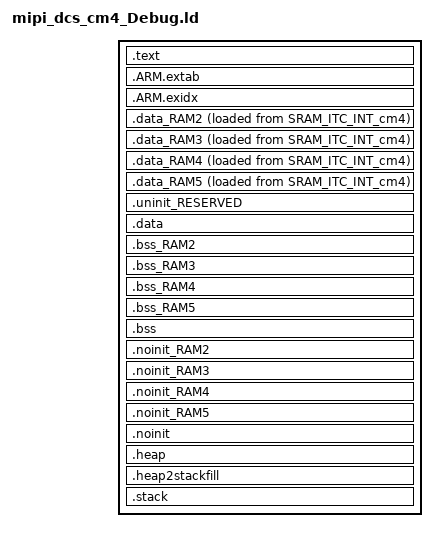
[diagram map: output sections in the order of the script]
/*
 * GENERATED FILE - DO NOT EDIT
 * Copyright 2008-2013 Code Red Technologies Ltd,
 * Copyright 2013-2024 NXP
 * Generated linker script file for MIMXRT1176xxxxx
 * Created from linkscript.ldt by FMCreateLinkLibraries
 * Using Freemarker v2.3.30
 * MCUXpresso IDE v11.8.0 [Build 1165] [2023-07-26] on May 7, 2024, 4:38:27 PM
 */

INCLUDE "mipi_dcs_cm4_Debug_library.ld"
INCLUDE "mipi_dcs_cm4_Debug_memory.ld"

ENTRY(ResetISR)

SECTIONS
{
     /* MAIN TEXT SECTION */
    .text : ALIGN(4)
    {
        FILL(0xff)
        __vectors_start__ = ABSOLUTE(.) ;
        KEEP(*(.isr_vector))
        /* Global Section Table */
        . = ALIGN(4) ;
        __section_table_start = .;
        __data_section_table = .;
        LONG(LOADADDR(.data));
        LONG(    ADDR(.data));
        LONG(  SIZEOF(.data));
        LONG(LOADADDR(.data_RAM2));
        LONG(    ADDR(.data_RAM2));
        LONG(  SIZEOF(.data_RAM2));
        LONG(LOADADDR(.data_RAM3));
        LONG(    ADDR(.data_RAM3));
        LONG(  SIZEOF(.data_RAM3));
        LONG(LOADADDR(.data_RAM4));
        LONG(    ADDR(.data_RAM4));
        LONG(  SIZEOF(.data_RAM4));
        LONG(LOADADDR(.data_RAM5));
        LONG(    ADDR(.data_RAM5));
        LONG(  SIZEOF(.data_RAM5));
        __data_section_table_end = .;
        __bss_section_table = .;
        LONG(    ADDR(.bss));
        LONG(  SIZEOF(.bss));
        LONG(    ADDR(.bss_RAM2));
        LONG(  SIZEOF(.bss_RAM2));
        LONG(    ADDR(.bss_RAM3));
        LONG(  SIZEOF(.bss_RAM3));
        LONG(    ADDR(.bss_RAM4));
        LONG(  SIZEOF(.bss_RAM4));
        LONG(    ADDR(.bss_RAM5));
        LONG(  SIZEOF(.bss_RAM5));
        __bss_section_table_end = .;
        __section_table_end = . ;
        /* End of Global Section Table */

        *(.after_vectors*)

       *(.text*)
       *(.rodata .rodata.* .constdata .constdata.*)
       . = ALIGN(4);
    } > SRAM_ITC_INT_cm4
    /*
     * for exception handling/unwind - some Newlib functions (in common
     * with C++ and STDC++) use this.
     */
    .ARM.extab : ALIGN(4)
    {
        *(.ARM.extab* .gnu.linkonce.armextab.*)
    } > SRAM_ITC_INT_cm4

    .ARM.exidx : ALIGN(4)
    {
        __exidx_start = .;
        *(.ARM.exidx* .gnu.linkonce.armexidx.*)
        __exidx_end = .;
    } > SRAM_ITC_INT_cm4
 
    _etext = .;
        
    /* DATA section for DTCM */

    .data_RAM2 : ALIGN(4)
    {
        FILL(0xff)
        PROVIDE(__start_data_RAM2 = .) ;
        PROVIDE(__start_data_DTCM = .) ;
        *(.ramfunc.$RAM2)
        *(.ramfunc.$DTCM)
        *(.data.$RAM2)
        *(.data.$DTCM)
        *(.data.$RAM2.*)
        *(.data.$DTCM.*)
        . = ALIGN(4) ;
        PROVIDE(__end_data_RAM2 = .) ;
        PROVIDE(__end_data_DTCM = .) ;
     } > DTCM AT>SRAM_ITC_INT_cm4

    /* DATA section for rpmsg_sh_mem */

    .data_RAM3 : ALIGN(4)
    {
        FILL(0xff)
        PROVIDE(__start_data_RAM3 = .) ;
        PROVIDE(__start_data_rpmsg_sh_mem = .) ;
        *(.ramfunc.$RAM3)
        *(.ramfunc.$rpmsg_sh_mem)
        *(.data.$RAM3)
        *(.data.$rpmsg_sh_mem)
        *(.data.$RAM3.*)
        *(.data.$rpmsg_sh_mem.*)
        . = ALIGN(4) ;
        PROVIDE(__end_data_RAM3 = .) ;
        PROVIDE(__end_data_rpmsg_sh_mem = .) ;
     } > rpmsg_sh_mem AT>SRAM_ITC_INT_cm4

    /* DATA section for NCACHE_REGION */

    .data_RAM4 : ALIGN(4)
    {
        FILL(0xff)
        PROVIDE(__start_data_RAM4 = .) ;
        PROVIDE(__start_data_NCACHE_REGION = .) ;
        *(.ramfunc.$RAM4)
        *(.ramfunc.$NCACHE_REGION)
       *(NonCacheable.init)
        *(.data.$RAM4)
        *(.data.$NCACHE_REGION)
        *(.data.$RAM4.*)
        *(.data.$NCACHE_REGION.*)
        . = ALIGN(4) ;
        PROVIDE(__end_data_RAM4 = .) ;
        PROVIDE(__end_data_NCACHE_REGION = .) ;
     } > NCACHE_REGION AT>SRAM_ITC_INT_cm4

    /* DATA section for SDRAM */

    .data_RAM5 : ALIGN(4)
    {
        FILL(0xff)
        PROVIDE(__start_data_RAM5 = .) ;
        PROVIDE(__start_data_SDRAM = .) ;
        *(.ramfunc.$RAM5)
        *(.ramfunc.$SDRAM)
        *(.data.$RAM5)
        *(.data.$SDRAM)
        *(.data.$RAM5.*)
        *(.data.$SDRAM.*)
        . = ALIGN(4) ;
        PROVIDE(__end_data_RAM5 = .) ;
        PROVIDE(__end_data_SDRAM = .) ;
     } > SDRAM AT>SRAM_ITC_INT_cm4

    /* MAIN DATA SECTION */
    .uninit_RESERVED (NOLOAD) : ALIGN(4)
    {
        _start_uninit_RESERVED = .;
        KEEP(*(.bss.$RESERVED*))
       . = ALIGN(4) ;
        _end_uninit_RESERVED = .;
    } > SRAM_ITC_INT_cm4 AT> SRAM_ITC_INT_cm4

    /* Main DATA section (SRAM_ITC_INT_cm4) */
    .data : ALIGN(4)
    {
       FILL(0xff)
       _data = . ;
       PROVIDE(__start_data_RAM = .) ;
       PROVIDE(__start_data_SRAM_ITC_INT_cm4 = .) ;
       *(vtable)
       *(.ramfunc*)
       KEEP(*(CodeQuickAccess))
       KEEP(*(DataQuickAccess))
       *(RamFunction)
       *(.data*)
       . = ALIGN(4) ;
       _edata = . ;
       PROVIDE(__end_data_RAM = .) ;
       PROVIDE(__end_data_SRAM_ITC_INT_cm4 = .) ;
    } > SRAM_ITC_INT_cm4 AT>SRAM_ITC_INT_cm4

    /* BSS section for DTCM */
    .bss_RAM2 (NOLOAD) : ALIGN(4)
    {
       PROVIDE(__start_bss_RAM2 = .) ;
       PROVIDE(__start_bss_DTCM = .) ;
       *(.bss.$RAM2)
       *(.bss.$DTCM)
       *(.bss.$RAM2.*)
       *(.bss.$DTCM.*)
       . = ALIGN (. != 0 ? 4 : 1) ; /* avoid empty segment */
       PROVIDE(__end_bss_RAM2 = .) ;
       PROVIDE(__end_bss_DTCM = .) ;
    } > DTCM AT> DTCM

    /* BSS section for rpmsg_sh_mem */
    .bss_RAM3 (NOLOAD) : ALIGN(4)
    {
       PROVIDE(__start_bss_RAM3 = .) ;
       PROVIDE(__start_bss_rpmsg_sh_mem = .) ;
       *(.bss.$RAM3)
       *(.bss.$rpmsg_sh_mem)
       *(.bss.$RAM3.*)
       *(.bss.$rpmsg_sh_mem.*)
       . = ALIGN (. != 0 ? 4 : 1) ; /* avoid empty segment */
       PROVIDE(__end_bss_RAM3 = .) ;
       PROVIDE(__end_bss_rpmsg_sh_mem = .) ;
    } > rpmsg_sh_mem AT> rpmsg_sh_mem

    /* BSS section for NCACHE_REGION */
    .bss_RAM4 (NOLOAD) : ALIGN(4)
    {
       PROVIDE(__start_bss_RAM4 = .) ;
       PROVIDE(__start_bss_NCACHE_REGION = .) ;
       *(NonCacheable)
       *(.bss.$RAM4)
       *(.bss.$NCACHE_REGION)
       *(.bss.$RAM4.*)
       *(.bss.$NCACHE_REGION.*)
       . = ALIGN (. != 0 ? 4 : 1) ; /* avoid empty segment */
       PROVIDE(__end_bss_RAM4 = .) ;
       PROVIDE(__end_bss_NCACHE_REGION = .) ;
    } > NCACHE_REGION AT> NCACHE_REGION

    /* BSS section for SDRAM */
    .bss_RAM5 (NOLOAD) : ALIGN(4)
    {
       PROVIDE(__start_bss_RAM5 = .) ;
       PROVIDE(__start_bss_SDRAM = .) ;
       *(.bss.$RAM5)
       *(.bss.$SDRAM)
       *(.bss.$RAM5.*)
       *(.bss.$SDRAM.*)
       . = ALIGN (. != 0 ? 4 : 1) ; /* avoid empty segment */
       PROVIDE(__end_bss_RAM5 = .) ;
       PROVIDE(__end_bss_SDRAM = .) ;
    } > SDRAM AT> SDRAM

    /* MAIN BSS SECTION */
    .bss (NOLOAD) : ALIGN(4)
    {
        _bss = .;
        PROVIDE(__start_bss_RAM = .) ;
        PROVIDE(__start_bss_SRAM_ITC_INT_cm4 = .) ;
        *(.bss*)
        *(COMMON)
        . = ALIGN(4) ;
        _ebss = .;
        PROVIDE(__end_bss_RAM = .) ;
        PROVIDE(__end_bss_SRAM_ITC_INT_cm4 = .) ;
        PROVIDE(end = .);
    } > SRAM_ITC_INT_cm4 AT> SRAM_ITC_INT_cm4

    /* NOINIT section for DTCM */
    .noinit_RAM2 (NOLOAD) : ALIGN(4)
    {
       PROVIDE(__start_noinit_RAM2 = .) ;
       PROVIDE(__start_noinit_DTCM = .) ;
       *(.noinit.$RAM2)
       *(.noinit.$DTCM)
       *(.noinit.$RAM2.*)
       *(.noinit.$DTCM.*)
       . = ALIGN(4) ;
       PROVIDE(__end_noinit_RAM2 = .) ;
       PROVIDE(__end_noinit_DTCM = .) ;
    } > DTCM AT> DTCM

    /* NOINIT section for rpmsg_sh_mem */
    .noinit_RAM3 (NOLOAD) : ALIGN(4)
    {
       PROVIDE(__start_noinit_RAM3 = .) ;
       PROVIDE(__start_noinit_rpmsg_sh_mem = .) ;
       *(.noinit.$RAM3)
       *(.noinit.$rpmsg_sh_mem)
       *(.noinit.$RAM3.*)
       *(.noinit.$rpmsg_sh_mem.*)
       . = ALIGN(4) ;
       PROVIDE(__end_noinit_RAM3 = .) ;
       PROVIDE(__end_noinit_rpmsg_sh_mem = .) ;
    } > rpmsg_sh_mem AT> rpmsg_sh_mem

    /* NOINIT section for NCACHE_REGION */
    .noinit_RAM4 (NOLOAD) : ALIGN(4)
    {
       PROVIDE(__start_noinit_RAM4 = .) ;
       PROVIDE(__start_noinit_NCACHE_REGION = .) ;
       *(.noinit.$RAM4)
       *(.noinit.$NCACHE_REGION)
       *(.noinit.$RAM4.*)
       *(.noinit.$NCACHE_REGION.*)
       . = ALIGN(4) ;
       PROVIDE(__end_noinit_RAM4 = .) ;
       PROVIDE(__end_noinit_NCACHE_REGION = .) ;
    } > NCACHE_REGION AT> NCACHE_REGION

    /* NOINIT section for SDRAM */
    .noinit_RAM5 (NOLOAD) : ALIGN(4)
    {
       PROVIDE(__start_noinit_RAM5 = .) ;
       PROVIDE(__start_noinit_SDRAM = .) ;
       *(.noinit.$RAM5)
       *(.noinit.$SDRAM)
       *(.noinit.$RAM5.*)
       *(.noinit.$SDRAM.*)
       . = ALIGN(4) ;
       PROVIDE(__end_noinit_RAM5 = .) ;
       PROVIDE(__end_noinit_SDRAM = .) ;
    } > SDRAM AT> SDRAM

    /* DEFAULT NOINIT SECTION */
    .noinit (NOLOAD): ALIGN(4)
    {
        _noinit = .;
        PROVIDE(__start_noinit_RAM = .) ;
        PROVIDE(__start_noinit_SRAM_ITC_INT_cm4 = .) ;
        *(.noinit*)
         . = ALIGN(4) ;
        _end_noinit = .;
       PROVIDE(__end_noinit_RAM = .) ;
       PROVIDE(__end_noinit_SRAM_ITC_INT_cm4 = .) ;        
    } > SRAM_ITC_INT_cm4 AT> SRAM_ITC_INT_cm4

    /* Reserve and place Heap within memory map */
    _HeapSize = 0x1000;
    .heap (NOLOAD) :  ALIGN(4)
    {
        _pvHeapStart = .;
        . += _HeapSize;
        . = ALIGN(4);
        _pvHeapLimit = .;
    } > SRAM_ITC_INT_cm4

     _StackSize = 0x1000;
     /* Reserve space in memory for Stack */
    .heap2stackfill (NOLOAD) :
    {
        . += _StackSize;
    } > SRAM_ITC_INT_cm4
    /* Locate actual Stack in memory map */
    .stack ORIGIN(SRAM_ITC_INT_cm4) + LENGTH(SRAM_ITC_INT_cm4) - _StackSize - 0 (NOLOAD) :  ALIGN(4)
    {
        _vStackBase = .;
        . = ALIGN(4);
        _vStackTop = . + _StackSize;
    } > SRAM_ITC_INT_cm4

    /* Provide basic symbols giving location and size of main text
     * block, including initial values of RW data sections. Note that
     * these will need extending to give a complete picture with
     * complex images (e.g multiple Flash banks).
     */
    _image_start = LOADADDR(.text);
    _image_end = LOADADDR(.data) + SIZEOF(.data);
    _image_size = _image_end - _image_start;
    /* Provide symbols for MIMXRT1170 parts for boot header generation code
     * to set image to be plain load image or XIP.
     * Config : Plain load image = false
     */
    _boot_loadaddr = ORIGIN(SRAM_ITC_INT_cm4);
    _boot_size = LENGTH(SRAM_ITC_INT_cm4);
}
